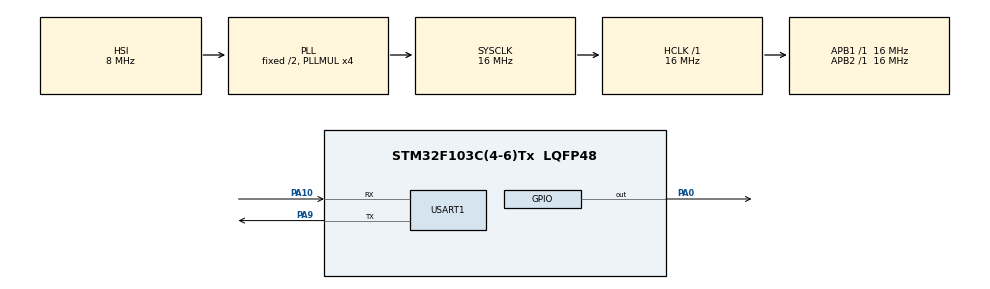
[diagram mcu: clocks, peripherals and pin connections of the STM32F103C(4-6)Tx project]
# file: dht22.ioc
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Mcu.Family=STM32F1
Mcu.Name=STM32F103C(4-6)Tx
Mcu.Package=LQFP48
NVIC.PriorityGroup=NVIC_PRIORITYGROUP_4
PA0-WKUP.Signal=GPIO_Output
PA10.Mode=Asynchronous
PA10.Signal=USART1_RX
PA9.Mode=Asynchronous
PA9.Signal=USART1_TX
ProjectManager.HeapSize=0x200
ProjectManager.StackSize=0x400
ProjectManager.TargetToolchain=STM32CubeIDE
RCC.AHBFreq_Value=16000000
RCC.APB1Freq_Value=16000000
RCC.APB1TimFreq_Value=16000000
RCC.APB2Freq_Value=16000000
RCC.APB2TimFreq_Value=16000000
RCC.HCLKFreq_Value=16000000
RCC.PLLMUL=RCC_PLL_MUL4
RCC.SYSCLKFreq_VALUE=16000000
RCC.SYSCLKSource=RCC_SYSCLKSOURCE_PLLCLK
RCC.USBFreq_Value=16000000
TIM1.Prescaler=15
USART1.VirtualMode=VM_ASYNC
VP_SYS_VS_ND.Mode=No_Debug
VP_TIM1_VS_ClockSourceINT.Mode=Internal
board=custom

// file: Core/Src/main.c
/* USER CODE BEGIN Header */
/**
  ******************************************************************************
  * @file           : main.c
  * @brief          : Main program body
  ******************************************************************************
  * @attention
  *
  * Copyright (c) 2024 STMicroelectronics.
  * All rights reserved.
  *
  * This software is licensed under terms that can be found in the LICENSE file
  * in the root directory of this software component.
  * If no LICENSE file comes with this software, it is provided AS-IS.
  *
  ******************************************************************************
  */
/* USER CODE END Header */
#include "main.h"

/* USER CODE BEGIN Includes */
#include<string.h>
#include<stdio.h>
/* USER CODE END Includes */

/* USER CODE BEGIN PD */
#define DHT22_Pin GPIO_PIN_0
#define DHT22_GPIO_Port GPIOA

/* USER CODE END PD */

TIM_HandleTypeDef htim1;

UART_HandleTypeDef huart1;

/* USER CODE BEGIN PV */
char message1[16];
char message2[16];
uint8_t TOUT = 0, CheckSum, i;
uint8_t T_Byte1, T_Byte2, RH_Byte1, RH_Byte2;
/* USER CODE END PV */

void SystemClock_Config(void);
static void MX_GPIO_Init(void);
static void MX_USART1_UART_Init(void);
static void MX_TIM1_Init(void);

/* USER CODE BEGIN 0 */
void start_signal(void) {
    GPIO_InitTypeDef GPIO_InitStruct = {0};
    GPIO_InitStruct.Pin = DHT22_Pin;
    GPIO_InitStruct.Mode = GPIO_MODE_OUTPUT_PP;
    GPIO_InitStruct.Pull = GPIO_NOPULL;
    GPIO_InitStruct.Speed = GPIO_SPEED_FREQ_LOW;
    HAL_GPIO_Init(DHT22_GPIO_Port, &GPIO_InitStruct);

    HAL_GPIO_WritePin(DHT22_GPIO_Port, DHT22_Pin, GPIO_PIN_RESET);
    HAL_Delay(18);
    HAL_GPIO_WritePin(DHT22_GPIO_Port, DHT22_Pin, GPIO_PIN_SET);
    delay_us(30);

    GPIO_InitStruct.Mode = GPIO_MODE_INPUT;
    HAL_GPIO_Init(DHT22_GPIO_Port, &GPIO_InitStruct);
}

uint8_t check_response(void) {
    TOUT = 0;
    __HAL_TIM_SET_COUNTER(&htim1, 0);
    while (!HAL_GPIO_ReadPin(DHT22_GPIO_Port, DHT22_Pin) && (__HAL_TIM_GET_COUNTER(&htim1) < 100)) {};
    if (__HAL_TIM_GET_COUNTER(&htim1) >= 100)
        return 0;

    __HAL_TIM_SET_COUNTER(&htim1, 0);
    while (HAL_GPIO_ReadPin(DHT22_GPIO_Port, DHT22_Pin) && (__HAL_TIM_GET_COUNTER(&htim1) < 100)) {};
    if (__HAL_TIM_GET_COUNTER(&htim1) >= 100)
        return 0;

    return 1;
}

uint8_t read_byte(void) {
    uint8_t num = 0;
    for (i = 0; i < 8; i++) {
        while (!HAL_GPIO_ReadPin(DHT22_GPIO_Port, DHT22_Pin)) {};
        __HAL_TIM_SET_COUNTER(&htim1, 0);
        while (HAL_GPIO_ReadPin(DHT22_GPIO_Port, DHT22_Pin)) {};
        if (__HAL_TIM_GET_COUNTER(&htim1) > 40)
            num |= (1 << (7 - i));
    }
    return num;
}

void delay_us(uint16_t us) {
    __HAL_TIM_SET_COUNTER(&htim1, 0);
    while (__HAL_TIM_GET_COUNTER(&htim1) < us);
}

void send_uart(char *string) {
    HAL_UART_Transmit(&huart1, (uint8_t*)string, strlen(string), HAL_MAX_DELAY);
}
/* USER CODE END 0 */

int main(void)
{

  /* USER CODE BEGIN 1 */
	 float Voltage_mV = 0;
	    float Temperature_C = 0;
	    float Temperature_F = 0;
	    char msg[50];
  /* USER CODE END 1 */

  /* MCU Configuration--------------------------------------------------------*/

  /* Reset of all peripherals, Initializes the Flash interface and the Systick. */
  HAL_Init();

  /* Configure the system clock */
  SystemClock_Config();

  /* Initialize all configured peripherals */
  MX_GPIO_Init();
  MX_USART1_UART_Init();
  MX_TIM1_Init();
  /* USER CODE BEGIN 2 */
  HAL_TIM_Base_Start(&htim1);
      send_uart("Initialization complete\n\r");
  /* USER CODE END 2 */

  /* Infinite loop */
  while (1)
  {

    /* USER CODE BEGIN 3 */
	  HAL_Delay(1000);
	         start_signal();
	         uint8_t check = check_response();
	         if (!check) {
	             send_uart("No response from the sensor\r\n");
	         } else {
	             RH_Byte1 = read_byte();
	             RH_Byte2 = read_byte();
	             T_Byte1 = read_byte();
	             T_Byte2 = read_byte();
	             CheckSum = read_byte();

	             uint16_t rh = (RH_Byte1 << 8) | RH_Byte2;
	             uint16_t temp = (T_Byte1 << 8) | T_Byte2;
	             uint8_t sign = 0;

	             if (temp > 0x8000) {
	                 temp &= 0x7FFF;
	                 sign = 1;
	             }

	             char rh_buf[5], temp_buf[5];
	             sprintf(rh_buf, "%03u", rh);
	             sprintf(temp_buf, "%03u", temp);

	             if (CheckSum == ((RH_Byte1 + RH_Byte2 + T_Byte1 + T_Byte2) & 0xFF)) {
	                 sprintf(msg, "RH = %03u.%1u %% ", rh / 10, rh % 10);
	                 send_uart(msg);

	                 sprintf(msg, "Temp = %c%03u.%1u C \r\n", sign ? '-' : ' ', temp / 10, temp % 10);
	                 send_uart(msg);

	             } else {
	                 send_uart("Checksum Error! Trying Again ...\r\n");
	             }
	         }

  }
  /* USER CODE END 3 */
}

void SystemClock_Config(void)
{
  RCC_OscInitTypeDef RCC_OscInitStruct = {0};
  RCC_ClkInitTypeDef RCC_ClkInitStruct = {0};

  /** Initializes the RCC Oscillators according to the specified parameters
  * in the RCC_OscInitTypeDef structure.
  */
  RCC_OscInitStruct.OscillatorType = RCC_OSCILLATORTYPE_HSI;
  RCC_OscInitStruct.HSIState = RCC_HSI_ON;
  RCC_OscInitStruct.HSICalibrationValue = RCC_HSICALIBRATION_DEFAULT;
  RCC_OscInitStruct.PLL.PLLState = RCC_PLL_ON;
  RCC_OscInitStruct.PLL.PLLSource = RCC_PLLSOURCE_HSI_DIV2;
  RCC_OscInitStruct.PLL.PLLMUL = RCC_PLL_MUL4;
  if (HAL_RCC_OscConfig(&RCC_OscInitStruct) != HAL_OK)
  {
    Error_Handler();
  }

  /** Initializes the CPU, AHB and APB buses clocks
  */
  RCC_ClkInitStruct.ClockType = RCC_CLOCKTYPE_HCLK|RCC_CLOCKTYPE_SYSCLK
                              |RCC_CLOCKTYPE_PCLK1|RCC_CLOCKTYPE_PCLK2;
  RCC_ClkInitStruct.SYSCLKSource = RCC_SYSCLKSOURCE_PLLCLK;
  RCC_ClkInitStruct.AHBCLKDivider = RCC_SYSCLK_DIV1;
  RCC_ClkInitStruct.APB1CLKDivider = RCC_HCLK_DIV1;
  RCC_ClkInitStruct.APB2CLKDivider = RCC_HCLK_DIV1;

  if (HAL_RCC_ClockConfig(&RCC_ClkInitStruct, FLASH_LATENCY_0) != HAL_OK)
  {
    Error_Handler();
  }
}

static void MX_TIM1_Init(void)
{

  TIM_ClockConfigTypeDef sClockSourceConfig = {0};
  TIM_MasterConfigTypeDef sMasterConfig = {0};

  htim1.Instance = TIM1;
  htim1.Init.Prescaler = 15;
  htim1.Init.CounterMode = TIM_COUNTERMODE_UP;
  htim1.Init.Period = 65535;
  htim1.Init.ClockDivision = TIM_CLOCKDIVISION_DIV1;
  htim1.Init.RepetitionCounter = 0;
  htim1.Init.AutoReloadPreload = TIM_AUTORELOAD_PRELOAD_DISABLE;
  if (HAL_TIM_Base_Init(&htim1) != HAL_OK)
  {
    Error_Handler();
  }
  sClockSourceConfig.ClockSource = TIM_CLOCKSOURCE_INTERNAL;
  if (HAL_TIM_ConfigClockSource(&htim1, &sClockSourceConfig) != HAL_OK)
  {
    Error_Handler();
  }
  sMasterConfig.MasterOutputTrigger = TIM_TRGO_RESET;
  sMasterConfig.MasterSlaveMode = TIM_MASTERSLAVEMODE_DISABLE;
  if (HAL_TIMEx_MasterConfigSynchronization(&htim1, &sMasterConfig) != HAL_OK)
  {
    Error_Handler();
  }

}

static void MX_USART1_UART_Init(void)
{

  huart1.Instance = USART1;
  huart1.Init.BaudRate = 115200;
  huart1.Init.WordLength = UART_WORDLENGTH_8B;
  huart1.Init.StopBits = UART_STOPBITS_1;
  huart1.Init.Parity = UART_PARITY_NONE;
  huart1.Init.Mode = UART_MODE_TX_RX;
  huart1.Init.HwFlowCtl = UART_HWCONTROL_NONE;
  huart1.Init.OverSampling = UART_OVERSAMPLING_16;
  if (HAL_UART_Init(&huart1) != HAL_OK)
  {
    Error_Handler();
  }

}

static void MX_GPIO_Init(void)
{
  GPIO_InitTypeDef GPIO_InitStruct = {0};

  /* GPIO Ports Clock Enable */
  __HAL_RCC_GPIOA_CLK_ENABLE();

  /*Configure GPIO pin Output Level */
  HAL_GPIO_WritePin(GPIOA, GPIO_PIN_0, GPIO_PIN_RESET);

  /*Configure GPIO pin : PA0 */
  GPIO_InitStruct.Pin = GPIO_PIN_0;
  GPIO_InitStruct.Mode = GPIO_MODE_OUTPUT_PP;
  GPIO_InitStruct.Pull = GPIO_NOPULL;
  GPIO_InitStruct.Speed = GPIO_SPEED_FREQ_LOW;
  HAL_GPIO_Init(GPIOA, &GPIO_InitStruct);

}

void Error_Handler(void)
{
  __disable_irq();
  while (1)
  {
  }
}
